VERSION "1.0"
NS_ :

BS_:

BU_: Vector__XXX Body Chassis Powertrain

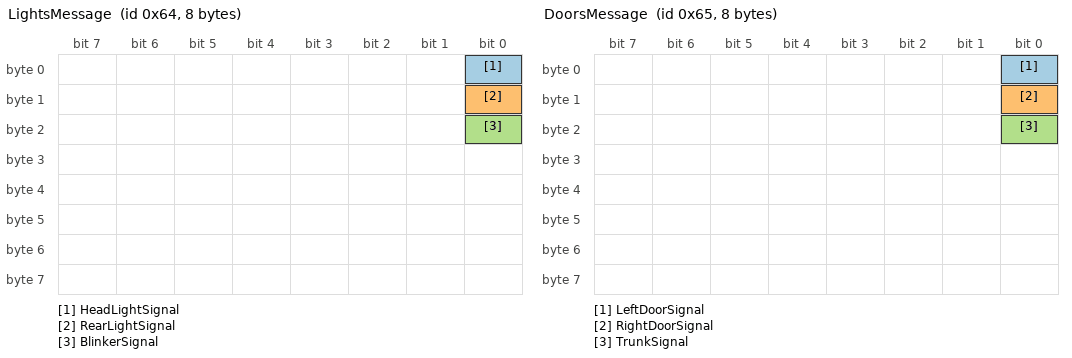
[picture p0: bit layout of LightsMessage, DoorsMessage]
BO_ 100 LightsMessage: 8 Body
 SG_ HeadLightSignal : 0|1@1+ (1,0) [0|1] "units" Chassis,Powertrain
 SG_ RearLightSignal : 8|1@1+ (1,0) [0|1] "units" Chassis,Powertrain
 SG_ BlinkerSignal : 16|1@1+ (1,0) [0|1] "units" Chassis,Powertrain

BO_ 101 DoorsMessage: 8 Body
 SG_ LeftDoorSignal : 0|1@1+ (1,0) [0|1] "units" Chassis,Powertrain
 SG_ RightDoorSignal : 8|1@1+ (1,0) [0|1] "units" Chassis,Powertrain
 SG_ TrunkSignal : 16|1@1+ (1,0) [0|1] "units" Chassis,Powertrain

BO_ 102 WindowsMessage: 8 Body
 SG_ LeftWindowSignal : 0|1@1+ (1,0) [0|1] "units" Chassis,Powertrain
 SG_ RightWindowSignal : 8|1@1+ (1,0) [0|1] "units" Chassis,Powertrain

BO_ 200 TransmissionMessage: 8 Chassis
 SG_ GearSignal : 0|8@1+ (1,0) [0|255] "units" Body,Powertrain

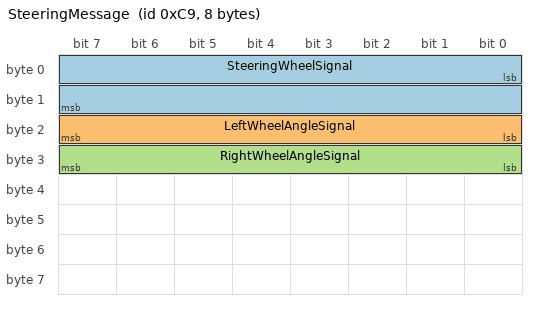
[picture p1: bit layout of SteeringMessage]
BO_ 201 SteeringMessage: 8 Chassis
 SG_ SteeringWheelSignal : 0|16@1+ (1,0) [-720|720] "Degree" Body,Powertrain
 SG_ LeftWheelAngleSignal : 16|8@1- (1,0) [-45|45] "Degree" Body,Powertrain
 SG_ RightWheelAngleSignal : 24|8@1- (1,0) [-45|45] "Degree" Body,Powertrain

BO_ 202 BrakeMessage: 8 Chassis
 SG_ BrakeSignal : 0|8@1+ (1,0) [0|100] "%" Body,Powertrain
 SG_ ParkingBrakeSignal : 8|8@1+ (1,0) [0|100] "%" Body,Powertrain

BO_ 300 EngineMessage: 8 Powertrain
 SG_ EngineRPMSignal : 0|32@1+ (1,0) [0|1000000] "RPM" Body,Chassis
 SG_ EngineTemperatureSignal : 32|16@1- (1,0) [-100|500] "Degree Celsius" Body,Chassis

BO_ 301 ThrottleMessage: 8 Powertrain
 SG_ ThrottleSignal : 0|8@1+ (1,0) [0|100] "%" Body,Chassis

BO_ 302 VehicleSpeedMessage: 8 Powertrain
 SG_ VehicleSpeedSignal : 0|16@1- (1,0) [-100|500] "km/h" Body,Chassis

BA_DEF_ BO_  "GenMsgCycleTime" INT 0 65535;
BA_ "GenMsgCycleTime" BO_ 100 200;

VAL_ 100 HeadLightSignal 0 "Off" 1 "On";
VAL_ 100 RearLightSignal 0 "Off" 1 "On";
VAL_ 100 BlinkerSignal 0 "Off" 1 "On";

VAL_ 101 LeftDoorSignal 0 "Closed" 1 "Open";
VAL_ 101 RightDoorSignal 0 "Closed" 1 "Open";
VAL_ 101 TrunkSignal 0 "Closed" 1 "Open";
